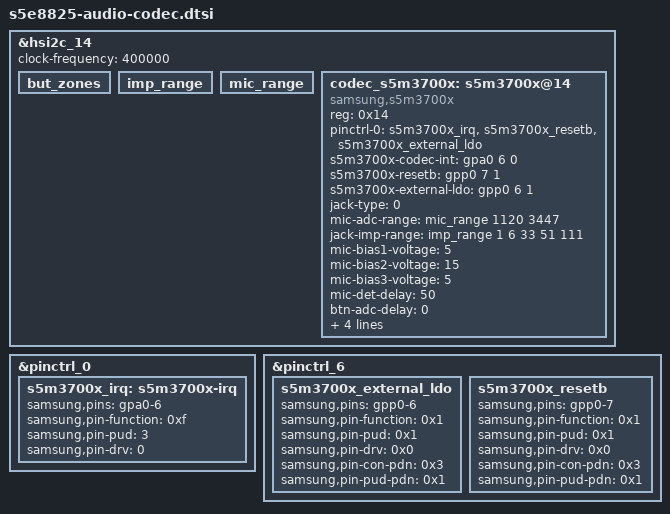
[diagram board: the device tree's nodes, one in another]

&hsi2c_14 {

	but_zones: but_zones {
		#list-but-cells = <3>;
	};

	imp_range: imp_range {
		#list-imp-cells = <5>;
	};

	mic_range: mic_range {
		#list-imp-cells = <2>;
	};
};

&pinctrl_0 {
	s5m3700x_irq: s5m3700x-irq {
		samsung,pins = "gpa0-6";
		samsung,pin-function = <0xf>;
		samsung,pin-pud = <3>;
		samsung,pin-drv = <0>;
	};
};

&pinctrl_6 {
	s5m3700x_external_ldo: s5m3700x_external_ldo {
		samsung,pins = "gpp0-6";
		samsung,pin-function = <0x1>;
		samsung,pin-pud = <0x1>;
		samsung,pin-drv = <0x0>;
		samsung,pin-con-pdn = <0x3>;
		samsung,pin-pud-pdn = <0x1>;
	};

	s5m3700x_resetb: s5m3700x_resetb {
		samsung,pins = "gpp0-7";
		samsung,pin-function = <0x1>;
		samsung,pin-pud = <0x1>;
		samsung,pin-drv = <0x0>;
		samsung,pin-con-pdn = <0x3>;
		samsung,pin-pud-pdn = <0x1>;
	};
};

&hsi2c_14 {
	#address-cells = <1>;
	#size-cells = <0>;
	status = "okay";
	clock-frequency = <400000>;

	codec_s5m3700x: s5m3700x@14 {
		status = "okay";
		compatible = "samsung,s5m3700x";
		#sound-dai-cells = <0>;
		reg = <0x14>;
		pinctrl-names = "default";
		pinctrl-0 = <&s5m3700x_irq>,<&s5m3700x_resetb>,<&s5m3700x_external_ldo>;

		s5m3700x-codec-int = <&gpa0 6 0>;
		s5m3700x-resetb = <&gpp0 7 1>;
		s5m3700x-external-ldo = <&gpp0 6 1>;

		/* 3.5PI: 0, USB: 1 */
		jack-type = <0>;

		mic-adc-range = <&mic_range 1120 3447>;
		jack-imp-range = <&imp_range 1 6 33 51 111>;
		mic-bias1-voltage = <5>;
		mic-bias2-voltage = <15>;
		mic-bias3-voltage = <5>;
		mic-det-delay = <50>;
		btn-adc-delay = <0>;
		btn-release-value = <1100>;
		but-zones-list = <&but_zones 226 0 117>, /* 0 ~ 70 ohm */
			<&but_zones 582 175 280>, /* 110 ~ 180 ohm */
			<&but_zones 115 315 430>, /* 210 ~ 290 ohm */
			<&but_zones 114 505 855>; /* 360 ~ 680 ohm */
	};
};

